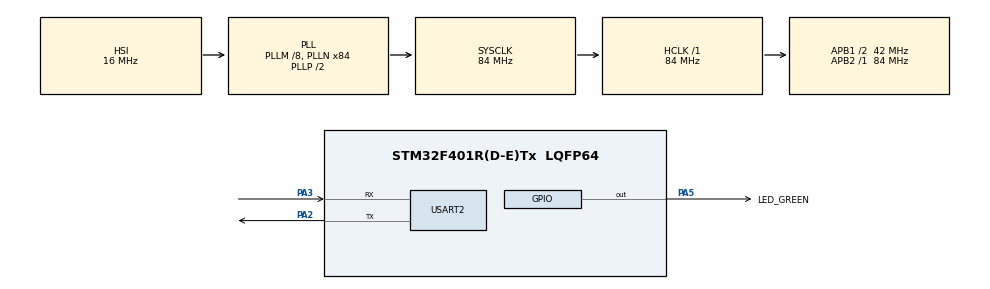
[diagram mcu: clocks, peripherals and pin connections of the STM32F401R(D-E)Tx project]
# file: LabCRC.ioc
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Mcu.Family=STM32F4
Mcu.Name=STM32F401R(D-E)Tx
Mcu.Package=LQFP64
NVIC.PriorityGroup=NVIC_PRIORITYGROUP_4
NVIC.USART2_IRQn=true\:0\:0\:false\:false\:true\:true\:true\:true
PA2.Mode=Asynchronous
PA2.Signal=USART2_TX
PA3.Mode=Asynchronous
PA3.Signal=USART2_RX
PA5.GPIO_Label=LED_GREEN
PA5.Signal=GPIO_Output
ProjectManager.HeapSize=0x200
ProjectManager.StackSize=0x400
ProjectManager.TargetToolchain=CMake
RCC.48MHZClocksFreq_Value=42000000
RCC.AHBFreq_Value=84000000
RCC.APB1CLKDivider=RCC_HCLK_DIV2
RCC.APB1Freq_Value=42000000
RCC.APB1TimFreq_Value=84000000
RCC.APB2Freq_Value=84000000
RCC.APB2TimFreq_Value=84000000
RCC.CortexFreq_Value=84000000
RCC.HCLKFreq_Value=84000000
RCC.HSE_VALUE=25000000
RCC.HSI_VALUE=16000000
RCC.LSE_VALUE=32768
RCC.PLLM=8
RCC.PLLN=84
RCC.SYSCLKFreq_VALUE=84000000
RCC.SYSCLKSource=RCC_SYSCLKSOURCE_PLLCLK
RCC.VCOOutputFreq_Value=168000000
USART2.VirtualMode=VM_ASYNC
VP_CRC_VS_CRC.Mode=CRC_Activate
board=custom

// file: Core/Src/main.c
/* USER CODE BEGIN Header */
/**
  ******************************************************************************
  * @file           : main.c
  * @brief          : Main program body
  ******************************************************************************
  * @attention
  *
  * Copyright (c) 2026 STMicroelectronics.
  * All rights reserved.
  *
  * This software is licensed under terms that can be found in the LICENSE file
  * in the root directory of this software component.
  * If no LICENSE file comes with this software, it is provided AS-IS.
  *
  ******************************************************************************
  */
/* USER CODE END Header */
#include "main.h"
#include "stm32f4xx_hal_crc.h"

/* USER CODE BEGIN Includes */
#include <stdio.h>
/* USER CODE END Includes */

/* USER CODE BEGIN PD */
/* CRC calculation length */
#define BUFFER_SIZE (0x4FFC)/4 // CRC over 0x08000000..0x08004FFB
/* Address where the CRC value are stored */
#define STD_CRC_ADDR (FLASH_BASE + 0x4FFC) // 0x08004FFC
/* USER CODE END PD */

CRC_HandleTypeDef hcrc;

UART_HandleTypeDef huart2;

/* USER CODE BEGIN PV */
__IO uint32_t u32CRCValueHw = 0;
__IO uint32_t u32CRCValueSoft= 0xFFFFFFFF;
const uint32_t *myDataBuffer;
/* USER CODE END PV */

void SystemClock_Config(void);
static void MX_GPIO_Init(void);
static void MX_CRC_Init(void);
static void MX_USART2_UART_Init(void);
/* USER CODE BEGIN PFP */
uint32_t Crc32(uint32_t Crc, uint32_t Data);
void Error_Handler(void);
/* USER CODE END PFP */

/* USER CODE BEGIN 0 */
/* CRC Calculation by software function */
uint32_t Crc32(uint32_t Crc, uint32_t Data) {
  uint8_t index;
  Crc ^= (Data);
  for (index = 0; index < 32; index++) {
    if (Crc & 0x80000000)
      Crc = (Crc << 1) ^ 0x04C11DB7; // Polynomial used in STM32
    else
      Crc = (Crc << 1);
  }
  return (Crc);
}
int __io_putchar(int ch) {
  HAL_UART_Transmit(&huart2, (uint8_t *)&ch, 1, 100);
  return ch;
}
/* USER CODE END 0 */

int main(void)
{

  /* USER CODE BEGIN 1 */
 uint16_t u16myDataBufferCount = BUFFER_SIZE;
 myDataBuffer = (uint32_t*) 0x08000000;
  /* USER CODE END 1 */

  /* MCU Configuration--------------------------------------------------------*/

  /* Reset of all peripherals, Initializes the Flash interface and the Systick. */
  HAL_Init();

  /* Configure the system clock */
  SystemClock_Config();

  /* Initialize all configured peripherals */
  MX_GPIO_Init();
  MX_CRC_Init();
  MX_USART2_UART_Init();
  /* USER CODE BEGIN 2 */
  printf("\n\r================================ CRC TEST ================================\n\r");
  u32CRCValueHw = HAL_CRC_Accumulate(&hcrc, (uint32_t *)FLASH_BASE, BUFFER_SIZE);
      /* CRC calculation by software */
      while (u16myDataBufferCount--) {
    u32CRCValueSoft = Crc32(u32CRCValueSoft, *myDataBuffer++);
  }

  /* 2 - Print the calculated checksum */
  printf("\tChecksum generated by STM32 hardware CRC Unit = 0x%08X\n\r",(unsigned int)u32CRCValueHw);
  printf("\tChecksum generated by STM32 software CRC = 0x%08X\n\r",(unsigned int)u32CRCValueSoft);
  /* 3 - Print the stored CRC */
  printf("\tChecksum stored at 0x%08X = 0x%08X\n\r", (unsigned int)STD_CRC_ADDR,*(unsigned int *)STD_CRC_ADDR);
  /* 4 - Check if the calculated CRC is equal the stored value */
  if (u32CRCValueHw == *(uint32_t *)STD_CRC_ADDR) {
    printf("CRC Check: OK...\n\r");
    printf("==========================================================================\n\r");
  } else {
    printf("CRC Check: Fail...\n\r");
    printf("==========================================================================\n\r");
  }
 /* USER CODE END 2 */

  /* Infinite loop */
  while (1)
  {

    /* USER CODE BEGIN 3 */
    /* Blink USER LED to indicates the running application */
    printf("Application running... \n\r");
    HAL_GPIO_TogglePin(LED_GREEN_GPIO_Port, LED_GREEN_Pin);
    HAL_Delay(1000);
  }
  /* USER CODE END 3 */
}

void SystemClock_Config(void)
{
  RCC_OscInitTypeDef RCC_OscInitStruct = {0};
  RCC_ClkInitTypeDef RCC_ClkInitStruct = {0};

  /** Configure the main internal regulator output voltage
  */
  __HAL_RCC_PWR_CLK_ENABLE();
  __HAL_PWR_VOLTAGESCALING_CONFIG(PWR_REGULATOR_VOLTAGE_SCALE2);

  /** Initializes the RCC Oscillators according to the specified parameters
  * in the RCC_OscInitTypeDef structure.
  */
  RCC_OscInitStruct.OscillatorType = RCC_OSCILLATORTYPE_HSI;
  RCC_OscInitStruct.HSIState = RCC_HSI_ON;
  RCC_OscInitStruct.HSICalibrationValue = RCC_HSICALIBRATION_DEFAULT;
  RCC_OscInitStruct.PLL.PLLState = RCC_PLL_ON;
  RCC_OscInitStruct.PLL.PLLSource = RCC_PLLSOURCE_HSI;
  RCC_OscInitStruct.PLL.PLLM = 8;
  RCC_OscInitStruct.PLL.PLLN = 84;
  RCC_OscInitStruct.PLL.PLLP = RCC_PLLP_DIV2;
  RCC_OscInitStruct.PLL.PLLQ = 4;
  if (HAL_RCC_OscConfig(&RCC_OscInitStruct) != HAL_OK)
  {
    Error_Handler();
  }

  /** Initializes the CPU, AHB and APB buses clocks
  */
  RCC_ClkInitStruct.ClockType = RCC_CLOCKTYPE_HCLK|RCC_CLOCKTYPE_SYSCLK
                              |RCC_CLOCKTYPE_PCLK1|RCC_CLOCKTYPE_PCLK2;
  RCC_ClkInitStruct.SYSCLKSource = RCC_SYSCLKSOURCE_PLLCLK;
  RCC_ClkInitStruct.AHBCLKDivider = RCC_SYSCLK_DIV1;
  RCC_ClkInitStruct.APB1CLKDivider = RCC_HCLK_DIV2;
  RCC_ClkInitStruct.APB2CLKDivider = RCC_HCLK_DIV1;

  if (HAL_RCC_ClockConfig(&RCC_ClkInitStruct, FLASH_LATENCY_2) != HAL_OK)
  {
    Error_Handler();
  }
}

static void MX_CRC_Init(void)
{

  hcrc.Instance = CRC;
  if (HAL_CRC_Init(&hcrc) != HAL_OK)
  {
    Error_Handler();
  }

}

static void MX_USART2_UART_Init(void)
{

  huart2.Instance = USART2;
  huart2.Init.BaudRate = 115200;
  huart2.Init.WordLength = UART_WORDLENGTH_8B;
  huart2.Init.StopBits = UART_STOPBITS_1;
  huart2.Init.Parity = UART_PARITY_NONE;
  huart2.Init.Mode = UART_MODE_TX_RX;
  huart2.Init.HwFlowCtl = UART_HWCONTROL_NONE;
  huart2.Init.OverSampling = UART_OVERSAMPLING_16;
  if (HAL_UART_Init(&huart2) != HAL_OK)
  {
    Error_Handler();
  }

}

static void MX_GPIO_Init(void)
{
  GPIO_InitTypeDef GPIO_InitStruct = {0};

  /* GPIO Ports Clock Enable */
  __HAL_RCC_GPIOA_CLK_ENABLE();

  /*Configure GPIO pin Output Level */
  HAL_GPIO_WritePin(LED_GREEN_GPIO_Port, LED_GREEN_Pin, GPIO_PIN_RESET);

  /*Configure GPIO pin : LED_GREEN_Pin */
  GPIO_InitStruct.Pin = LED_GREEN_Pin;
  GPIO_InitStruct.Mode = GPIO_MODE_OUTPUT_PP;
  GPIO_InitStruct.Pull = GPIO_NOPULL;
  GPIO_InitStruct.Speed = GPIO_SPEED_FREQ_LOW;
  HAL_GPIO_Init(LED_GREEN_GPIO_Port, &GPIO_InitStruct);

}

void Error_Handler(void)
{
  __disable_irq();
  while (1)
  {
  }
}
